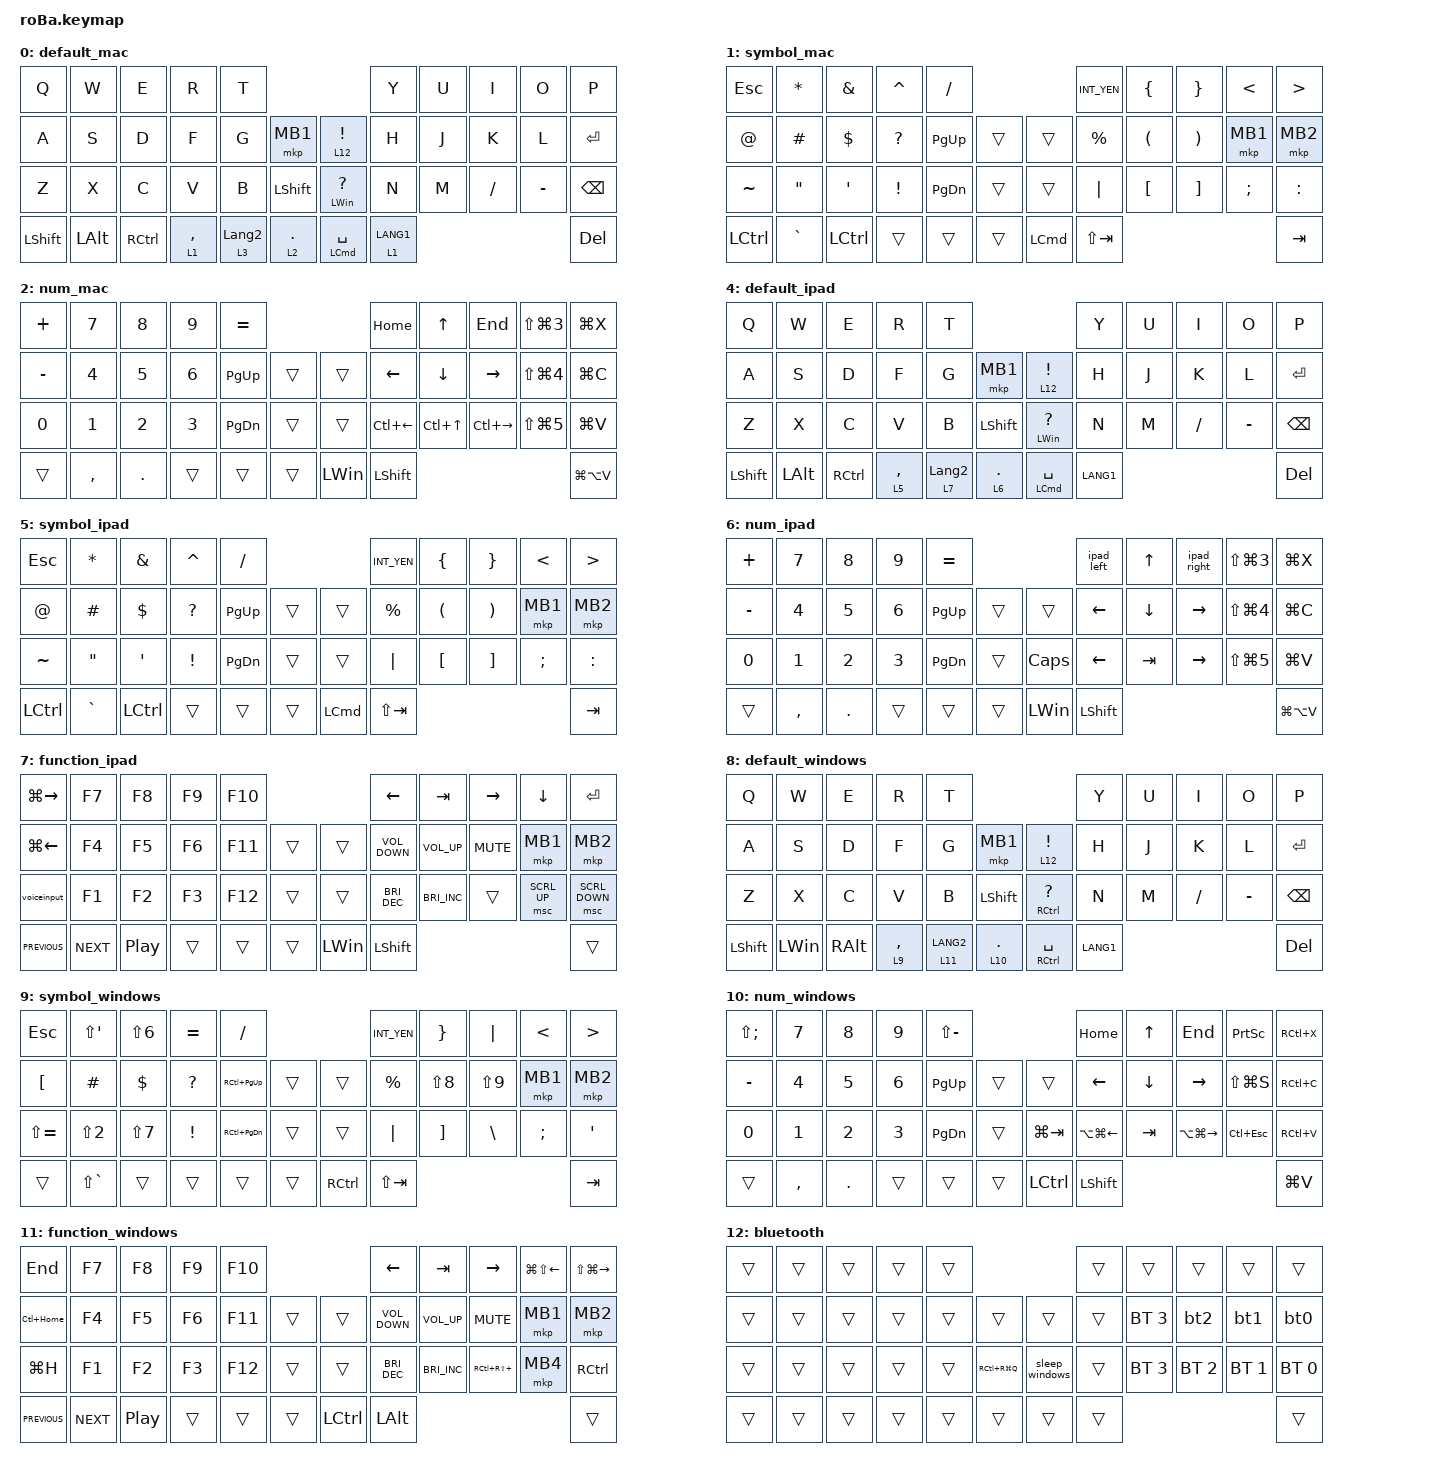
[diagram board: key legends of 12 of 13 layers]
#include <behaviors.dtsi>
#include <dt-bindings/zmk/bt.h>
#include <dt-bindings/zmk/keys.h>
#include <dt-bindings/zmk/pointing.h>

#define ZMK_POINTING_DEFAULT_SCRL_VAL 80

&mt {
    flavor = "balanced";
    quick-tap-ms = <0>;
};

&trackball {
    scroll-layers = <3 7 11>;

    // arrows {
    //     layers = <3>;
    //     bindings =
    //         <&kp RIGHT_ARROW>,
    //         <&kp LEFT_ARROW>,
    //         <&kp UP_ARROW>,
    //         <&kp DOWN_ARROW>;
    //     tick = <10>;
    //     wait-ms = <5>;
    //     tap-ms = <5>;
    // };
};

/ {
    combos {
        compatible = "zmk,combos";

        jis_underbar {
            bindings = <&kp INT_RO>;
            key-positions = <32 34>;
            layers = <9>;
        };

        jis_underbar2 {
            bindings = <&kp INT_RO>;
            key-positions = <32 27>;
            layers = <9>;
        };
    };

    macros {
        bt0: to_layer_0 {
            compatible = "zmk,behavior-macro";
            #binding-cells = <0>;
            bindings = <&bt BT_SEL 0>, <&macro_wait_time 200>, <&to 0>;

            label = "TO_LAYER_0";
        };

        bt2: bt2 {
            compatible = "zmk,behavior-macro";
            #binding-cells = <0>;
            bindings = <&bt BT_SEL 2>, <&macro_wait_time 200>, <&to 8>;

            label = "BT2";
        };

        bt1: bt1 {
            compatible = "zmk,behavior-macro";
            #binding-cells = <0>;
            bindings = <&bt BT_SEL 1>, <&macro_wait_time 200>, <&to 4>;

            label = "BT1";
        };

        sleep_windows: sleep_windows {
            compatible = "zmk,behavior-macro";
            #binding-cells = <0>;
            bindings =
                <&kp LG(X)>,
                <&macro_wait_time 200>,
                <&kp U>,
                <&macro_wait_time 200>,
                <&kp S>;

            label = "SLEEP_WINDOWS";
        };

        voiceinput: voiceinput {
            compatible = "zmk,behavior-macro";
            #binding-cells = <0>;
            bindings = <&kp CAPSLOCK &kp SPACE>;
            label = "VOICEINPUT";
        };

        appswitcher: appswitcher {
            compatible = "zmk,behavior-macro";
            #binding-cells = <0>;
            bindings = <&kp CAPSLOCK &kp UP_ARROW>;
            label = "APPSWITCHER";
        };

        right: right {
            compatible = "zmk,behavior-macro";
            #binding-cells = <0>;
            bindings = <&kp CAPS &kp RIGHT>;
            label = "RIGHT";
        };

        left: left {
            compatible = "zmk,behavior-macro";
            #binding-cells = <0>;
            bindings = <&kp CAPSLOCK &kp LEFT>;
            label = "LEFT";
        };

        ipad_left: ipad_left {
            compatible = "zmk,behavior-macro";
            #binding-cells = <0>;
            bindings =
                <&macro_press>,
                <&kp LCTRL &kp CAPS>,
                <&macro_tap>,
                <&kp LEFT>,
                <&macro_release>,
                <&kp LCTRL &kp CAPS>;

            label = "IPAD_LEFT";
        };

        ipad_right: ipad_right {
            compatible = "zmk,behavior-macro";
            #binding-cells = <0>;
            bindings =
                <&macro_press>,
                <&kp LCTRL &kp CAPS>,
                <&macro_tap>,
                <&kp RIGHT>,
                <&macro_release>,
                <&kp LCTRL &kp CAPS>;

            label = "IPAD_RIGHT";
        };
    };

    behaviors {
        lt_to_layer_0: lt_to_layer_0 {
            compatible = "zmk,behavior-hold-tap";
            label = "LAYER_TAP_TO_0";
            bindings = <&mo>, <&bt0>;

            #binding-cells = <2>;
            tapping-term-ms = <200>;
        };

        encoder_msc_down_up: encoder_msc_down_up {
            compatible = "zmk,behavior-sensor-rotate";
            label = "ENCODER_MSC_DOWN_UP";
            #sensor-binding-cells = <0>;
            bindings = <&msc SCRL_DOWN>, <&msc SCRL_UP>;

            tap-ms = <20>;
        };
    };

    keymap {
        compatible = "zmk,keymap";

        default_mac {
            bindings = <
&kp Q           &kp W         &kp E      &kp R        &kp T                                                        &kp Y        &kp U  &kp I      &kp O      &kp P
&kp A           &kp S         &kp D      &kp F        &kp G             &mkp MB1            &lt 12 EXCLAMATION     &kp H        &kp J  &kp K      &kp L      &kp ENTER
&kp Z           &kp X         &kp C      &kp V        &kp B             &kp LEFT_SHIFT      &mt LEFT_WIN QUESTION  &kp N        &kp M  &kp SLASH  &kp MINUS  &kp BACKSPACE
&kp LEFT_SHIFT  &kp LEFT_ALT  &kp RCTRL  &lt 1 COMMA  &lt 3 LANGUAGE_2  &lt 2 PERIOD        &mt LCMD SPACE         &lt 1 LANG1                               &kp DEL
            >;

            sensor-bindings = <&encoder_msc_down_up>;
        };

        symbol_mac {
            bindings = <
&kp ESCAPE   &kp ASTRK          &kp AMPERSAND  &kp CARET        &kp SLASH                            &kp INT_YEN  &kp LEFT_BRACE        &kp RIGHT_BRACE        &kp LESS_THAN  &kp GREATER_THAN
&kp AT_SIGN  &kp HASH           &kp DOLLAR     &kp QUESTION     &kp PAGE_UP    &trans      &trans    &kp PERCENT  &kp LEFT_PARENTHESIS  &kp RIGHT_PARENTHESIS  &mkp MB1       &mkp MB2
&kp TILDE    &kp DOUBLE_QUOTES  &kp SQT        &kp EXCLAMATION  &kp PAGE_DOWN  &trans      &trans    &kp PIPE     &kp LEFT_BRACKET      &kp RIGHT_BRACKET      &kp SEMICOLON  &kp COLON
&kp LCTRL    &kp GRAVE          &kp LCTRL      &trans           &trans         &trans      &kp LCMD  &kp LS(TAB)                                                              &kp TAB
            >;

            sensor-bindings = <&inc_dec_kp SLASH MINUS>;
        };

        num_mac {
            bindings = <
&kp PLUS      &kp NUMBER_7  &kp NUMBER_8  &kp NUMBER_9  &kp EQUAL                                &kp HOME        &kp UP            &kp END        &kp LS(LG(NUMBER_3))  &kp LG(X)
&kp MINUS     &kp NUMBER_4  &kp NUMBER_5  &kp NUMBER_6  &kp PAGE_UP    &trans      &trans        &kp LEFT        &kp DOWN          &kp RIGHT      &kp LS(LG(NUMBER_4))  &kp LG(C)
&kp NUMBER_0  &kp NUMBER_1  &kp NUMBER_2  &kp NUMBER_3  &kp PAGE_DOWN  &trans      &trans        &kp LC(LEFT)    &kp LC(UP_ARROW)  &kp LC(RIGHT)  &kp LS(LG(NUMBER_5))  &kp LG(V)
&trans        &kp COMMA     &kp PERIOD    &trans        &trans         &trans      &kp LEFT_WIN  &kp LEFT_SHIFT                                                         &kp LG(LA(V))
            >;
        };

        function_mac {
            bindings = <
&kp LC(E)       &kp F7      &kp F8            &kp F9  &kp F10                                 &kp LEFT              &kp TAB               &kp RIGHT   &kp DOWN  &kp ENTER
&kp LC(A)       &kp F4      &kp F5            &kp F6  &kp F11  &trans      &kp RG(RS(E))      &kp C_VOLUME_DOWN     &kp C_VOLUME_UP       &kp K_MUTE  &mkp MB1  &mkp MB2
&kp CAPSLOCK    &kp F1      &kp F2            &kp F3  &kp F12  &trans      &kp RG(RA(RS(E)))  &kp C_BRIGHTNESS_DEC  &kp C_BRIGHTNESS_INC  &kp CAPS    &mkp MB4  &mkp MB5
&kp C_PREVIOUS  &kp C_NEXT  &kp C_PLAY_PAUSE  &trans  &trans   &trans      &kp LEFT_WIN       &kp RG(QUESTION)                                                  &trans
            >;

            sensor-bindings = <&inc_dec_kp LC(PAGE_UP) LC(PAGE_DOWN)>;
        };

        default_ipad {
            bindings = <
&kp Q           &kp W         &kp E      &kp R        &kp T                                                        &kp Y      &kp U  &kp I      &kp O      &kp P
&kp A           &kp S         &kp D      &kp F        &kp G             &mkp MB1            &lt 12 EXCLAMATION     &kp H      &kp J  &kp K      &kp L      &kp ENTER
&kp Z           &kp X         &kp C      &kp V        &kp B             &kp LEFT_SHIFT      &mt LEFT_WIN QUESTION  &kp N      &kp M  &kp SLASH  &kp MINUS  &kp BACKSPACE
&kp LEFT_SHIFT  &kp LEFT_ALT  &kp RCTRL  &lt 5 COMMA  &lt 7 LANGUAGE_2  &lt 6 PERIOD        &mt LCMD SPACE         &kp LANG1                               &kp DEL
            >;

            sensor-bindings = <&encoder_msc_down_up>;
        };

        symbol_ipad {
            bindings = <
&kp ESCAPE   &kp ASTRK          &kp AMPERSAND  &kp CARET        &kp SLASH                            &kp INT_YEN  &kp LEFT_BRACE        &kp RIGHT_BRACE        &kp LESS_THAN  &kp GREATER_THAN
&kp AT_SIGN  &kp HASH           &kp DOLLAR     &kp QUESTION     &kp PAGE_UP    &trans      &trans    &kp PERCENT  &kp LEFT_PARENTHESIS  &kp RIGHT_PARENTHESIS  &mkp MB1       &mkp MB2
&kp TILDE    &kp DOUBLE_QUOTES  &kp SQT        &kp EXCLAMATION  &kp PAGE_DOWN  &trans      &trans    &kp PIPE     &kp LEFT_BRACKET      &kp RIGHT_BRACKET      &kp SEMICOLON  &kp COLON
&kp LCTRL    &kp GRAVE          &kp LCTRL      &trans           &trans         &trans      &kp LCMD  &kp LS(TAB)                                                              &kp TAB
            >;

            sensor-bindings = <&inc_dec_kp SLASH MINUS>;
        };

        num_ipad {
            bindings = <
&kp PLUS      &kp NUMBER_7  &kp NUMBER_8  &kp NUMBER_9  &kp EQUAL                                &ipad_left      &kp UP    &ipad_right  &kp LS(LG(NUMBER_3))  &kp LG(X)
&kp MINUS     &kp NUMBER_4  &kp NUMBER_5  &kp NUMBER_6  &kp PAGE_UP    &trans      &trans        &kp LEFT        &kp DOWN  &kp RIGHT    &kp LS(LG(NUMBER_4))  &kp LG(C)
&kp NUMBER_0  &kp NUMBER_1  &kp NUMBER_2  &kp NUMBER_3  &kp PAGE_DOWN  &trans      &kp CAPS      &kp LEFT_ARROW  &kp TAB   &kp RIGHT    &kp LS(LG(NUMBER_5))  &kp LG(V)
&trans        &kp COMMA     &kp PERIOD    &trans        &trans         &trans      &kp LEFT_WIN  &kp LEFT_SHIFT                                               &kp LG(LA(V))
            >;
        };

        function_ipad {
            bindings = <
&kp LG(RIGHT)   &kp F7      &kp F8            &kp F9  &kp F10                            &kp LEFT              &kp TAB               &kp RIGHT   &kp DOWN      &kp ENTER
&kp LG(LEFT)    &kp F4      &kp F5            &kp F6  &kp F11  &trans      &trans        &kp C_VOLUME_DOWN     &kp C_VOLUME_UP       &kp K_MUTE  &mkp MB1      &mkp MB2
&voiceinput     &kp F1      &kp F2            &kp F3  &kp F12  &trans      &trans        &kp C_BRIGHTNESS_DEC  &kp C_BRIGHTNESS_INC  &trans      &msc SCRL_UP  &msc SCRL_DOWN
&kp C_PREVIOUS  &kp C_NEXT  &kp C_PLAY_PAUSE  &trans  &trans   &trans      &kp LEFT_WIN  &kp LEFT_SHIFT                                                        &trans
            >;

            sensor-bindings = <&inc_dec_kp LC(PAGE_UP) LC(PAGE_DOWN)>;
        };

        default_windows {
            bindings = <
&kp Q           &kp W         &kp E          &kp R        &kp T                                                 &kp Y      &kp U  &kp I      &kp O      &kp P
&kp A           &kp S         &kp D          &kp F        &kp G         &mkp MB1            &lt 12 EXCLAMATION  &kp H      &kp J  &kp K      &kp L      &kp ENTER
&kp Z           &kp X         &kp C          &kp V        &kp B         &kp LEFT_SHIFT      &mt RCTRL QUESTION  &kp N      &kp M  &kp SLASH  &kp MINUS  &kp BACKSPACE
&kp LEFT_SHIFT  &kp LEFT_WIN  &kp RIGHT_ALT  &lt 9 COMMA  &lt 11 LANG2  &lt 10 PERIOD       &mt RCTRL SPACE     &kp LANG1                               &kp DEL
            >;

            sensor-bindings = <&encoder_msc_down_up>;
        };

        symbol_windows {
            bindings = <
&kp ESCAPE        &kp LS(SQT)       &kp LS(NUMBER_6)  &kp EQUAL        &kp SLASH                                 &kp INT_YEN  &kp RIGHT_BRACE    &kp PIPE          &kp LESS_THAN  &kp GREATER_THAN
&kp LEFT_BRACKET  &kp HASH          &kp DOLLAR        &kp QUESTION     &kp RC(PAGE_UP)    &trans      &trans     &kp PERCENT  &kp LS(NUMBER_8)   &kp LS(NUMBER_9)  &mkp MB1       &mkp MB2
&kp LS(EQUAL)     &kp LS(NUMBER_2)  &kp LS(NUMBER_7)  &kp EXCLAMATION  &kp RC(PAGE_DOWN)  &trans      &trans     &kp PIPE     &kp RIGHT_BRACKET  &kp BACKSLASH     &kp SEMICOLON  &kp SQT
&trans            &kp LS(GRAVE)     &trans            &trans           &trans             &trans      &kp RCTRL  &kp LS(TAB)                                                      &kp TAB
            >;

            sensor-bindings = <&inc_dec_kp SLASH MINUS>;
        };

        num_windows {
            bindings = <
&kp LS(SEMICOLON)  &kp NUMBER_7  &kp NUMBER_8  &kp NUMBER_9  &kp LS(MINUS)                           &kp HOME          &kp UP    &kp END            &kp PRINTSCREEN  &kp RC(X)
&kp MINUS          &kp NUMBER_4  &kp NUMBER_5  &kp NUMBER_6  &kp PAGE_UP    &trans      &trans       &kp LEFT          &kp DOWN  &kp RIGHT          &kp LS(LG(S))    &kp RC(C)
&kp NUMBER_0       &kp NUMBER_1  &kp NUMBER_2  &kp NUMBER_3  &kp PAGE_DOWN  &trans      &kp LG(TAB)  &kp LA(LG(LEFT))  &kp TAB   &kp LA(LG(RIGHT))  &kp LC(ESC)      &kp RC(V)
&trans             &kp COMMA     &kp PERIOD    &trans        &trans         &trans      &kp LCTRL    &kp LEFT_SHIFT                                                  &kp LG(V)
            >;
        };

        function_windows {
            bindings = <
&kp END         &kp F7      &kp F8            &kp F9  &kp F10                         &kp LEFT              &kp TAB               &kp RIGHT         &kp LG(LS(LEFT))  &kp LS(LG(RIGHT))
&kp LC(HOME)    &kp F4      &kp F5            &kp F6  &kp F11  &trans      &trans     &kp C_VOLUME_DOWN     &kp C_VOLUME_UP       &kp K_MUTE        &mkp MB1          &mkp MB2
&kp LG(H)       &kp F1      &kp F2            &kp F3  &kp F12  &trans      &trans     &kp C_BRIGHTNESS_DEC  &kp C_BRIGHTNESS_INC  &kp RC(RS(PLUS))  &mkp MB4          &kp RCTRL
&kp C_PREVIOUS  &kp C_NEXT  &kp C_PLAY_PAUSE  &trans  &trans   &trans      &kp LCTRL  &kp LEFT_ALT                                                                    &trans
            >;

            sensor-bindings = <&inc_dec_kp LC(PAGE_UP) LC(PAGE_DOWN)>;
        };

        bluetooth {
            bindings = <
&trans  &trans  &trans  &trans  &trans                                     &trans  &trans        &trans        &trans        &trans
&trans  &trans  &trans  &trans  &trans  &trans             &trans          &trans  &bt BT_SEL 3  &bt2          &bt1          &bt0
&trans  &trans  &trans  &trans  &trans  &kp RC(RG(Q))      &sleep_windows  &trans  &bt BT_SEL 3  &bt BT_SEL 2  &bt BT_SEL 1  &bt BT_SEL 0
&trans  &trans  &trans  &trans  &trans  &trans             &trans          &trans                                            &trans
            >;
        };
    };
};
